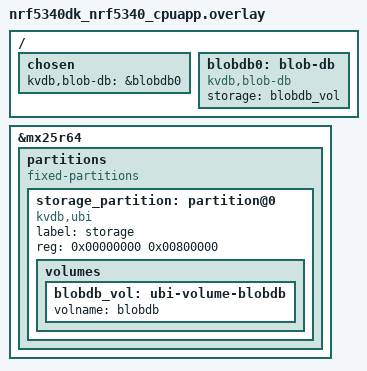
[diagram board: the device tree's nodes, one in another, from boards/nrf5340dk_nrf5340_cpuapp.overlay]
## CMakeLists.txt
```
#-------------------------------------------------------------------------------
# app_cbor_persondb — CBOR person/credential database over the L2 Map shape
#
# Copyright (c) 2026
# SPDX-License-Identifier: Apache-2.0

cmake_minimum_required(VERSION 3.13.1)
find_package(Zephyr REQUIRED HINTS $ENV{ZEPHYR_BASE})

project(app_cbor_persondb LANGUAGES C)

# One directory per layer, added bottom-up (DESIGN.md §7). Each subdirectory
# contributes its own sources and publishes its own header directory, so the
# build file has the same shape as the design — and a new dependency between
# layers is a visible edit here, not an #include someone slipped in.
#
#   ui/        frontends: parse and print only                    (F15)
#     |
#   scenario/  operations on a population: fill, verify, measure   (F14)
#     |   \_______________________
#     |                           |
#   persondb/                  dataset/
#     the person management       the synthetic population: a pure
#     API, and the only layer     function of an index. Uses persondb's
#     that touches storage        record type; touches no storage.
#     (F12, R-H)                                              (F6)
#     \__ person_cbor: the wire format, private to persondb
#
add_subdirectory(dataset)
add_subdirectory(persondb)
add_subdirectory(scenario)
add_subdirectory(ui)
```

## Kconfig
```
# app_cbor_persondb — Kconfig entry point.
#
# Copyright (c) 2026
# SPDX-License-Identifier: Apache-2.0

module = APP_CBOR_PERSONDB
module-str = APP_CBOR_PERSONDB
source "subsys/logging/Kconfig.template.log_config"

choice APP_CBOR_PERSONDB_FRONTEND
	prompt "Frontend"
	default APP_CBOR_PERSONDB_FRONTEND_BENCH
	help
	  Both frontends drive the same scenario layer (DESIGN.md §9); they
	  differ only in how the operations are invoked and rendered.

config APP_CBOR_PERSONDB_FRONTEND_BENCH
	bool "Automatic benchmark run"
	help
	  Unattended: open, prepare, fill (resuming in batches), verify,
	  mutate, re-verify, benchmark, report, exit. The source of RESULTS.md.

config APP_CBOR_PERSONDB_FRONTEND_SHELL
	bool "Interactive shell"
	select SHELL
	imply BLOB_DB_SHELL
	help
	  The same operations under "persondb <cmd>", for poking a live store
	  on the board — including power-cutting a fill and inspecting what
	  survived. The read-only "blob_db <cmd>" group (BLOB_DB_SHELL) comes
	  with it, to see how that data lies across the buckets.

endchoice

config APP_CBOR_PERSONDB_TUI
	bool "Full-screen browser under the shell (persondb tui)"
	default y
	depends on APP_CBOR_PERSONDB_FRONTEND_SHELL
	help
	  Adds "persondb tui": a VT100 full-screen view of every stored
	  person, with dialogs to add and delete persons, grant and revoke
	  permissions, add and remove cards, rename a person and set the
	  days their cards are valid. It draws over the shell's own terminal
	  and hands it back on 'q', Ctrl-C or Ctrl-D. Plain VT100 and DEC
	  line drawing, 80x24, so any serial terminal will do.

	  Costs ~3.4 KB of .bss (measured with nm): the page cache, the
	  selected person, a read buffer and 128 remembered page starts.
	  Nothing on the shell thread's stack beyond what the shell commands
	  already use.

# The shell frontend runs the scenario layer on the SHELL thread, not on main,
# and blob_db builds every slot in a CONFIG_BLOB_DB_MAX_PAYLOAD_LEN + 46 byte
# stack frame (FINDINGS.md B5, job 3). prj.conf sizes CONFIG_MAIN_STACK_SIZE for
# that chain — 19 870 B measured with -fstack-usage — but Zephyr's shell thread
# defaults to 2 048 B, so every persondb command overflowed it and halted the
# system on the first keystroke. Give the shell thread what main gets.
#
# Costs ~26 KB of RAM, and only when the shell frontend is selected.
config SHELL_STACK_SIZE
	default 28672 if APP_CBOR_PERSONDB_FRONTEND_SHELL

config APP_CBOR_PERSONDB_N_PERSONS
	int "Number of persons in the dataset"
	default 8000
	range 8 200000
	help
	  Dataset scale, and a FIXED CONSTANT OF THE BENCHMARK. Two runs are
	  only comparable if they used the same number, so treat changing it
	  as defining a new benchmark rather than tuning this one.

	  8 000 since DESIGN.md §6.5. It was 10 000, chosen once to put the
	  store at roughly half the nRF5340-DK's 8 MiB external flash. The
	  two-instance layout cannot reach that: the measured ceiling is
	  9 670 persons, because kvhash's bucket directory is a 16 384 B blob
	  that blob_db can no longer place once the store is about half full
	  (FINDINGS.md K13).

	  8 000 is the re-sized constant, not the ceiling. The gap is
	  deliberate: 9 670 is where a FRESH fill dies, and a benchmark that
	  sits at its own cliff fails later, on the DK, hours into a fill, for
	  reasons that look random. 17 % under it, the store holds at 41.3 %
	  live across repeated fill/mutate/bench rounds with no drift — that
	  was measured over three consecutive runs, not assumed.

	  The fill percentage remains an output, not a target (DESIGN.md
	  §6.3). If the stack gets more efficient and the same 8 000 persons
	  come to occupy 30 %, that is the improvement being measured — do
	  not raise this to compensate. Raising it to chase the ceiling is
	  how the number stops meaning anything.

	  Lower it for a quick run; the smoke scenario in sample.yaml uses 200.

config APP_CBOR_PERSONDB_FILL_BATCH
	int "Persons per resumable fill batch"
	default 256
	range 1 65536
	help
	  Progress is committed to the superblock after each batch, so an
	  interrupted fill resumes from the last committed count instead of
	  starting over. Replaying a partial batch rewrites identical values,
	  so replay is free.

config APP_CBOR_PERSONDB_VERIFY_SAMPLES
	int "Persons verified per run"
	default 256
	range 1 65536
	help
	  Verifying all 8 000 persons costs roughly 5 minutes per pass on the
	  DK, so a run checks a deterministic spread instead. Every sampled
	  person is compared field by field against the generator, and each of
	  its cards is resolved back through the credential index.

config APP_CBOR_PERSONDB_MUTATE_COUNT
	int "Persons touched per mutation round"
	default 64
	range 1 4096
	help
	  Each run revokes the previous revision's temporary cards and grants
	  the next revision's, exercising both fail-safe orderings
	  (DESIGN.md F5) and proving across a reboot that the previous run's
	  writes survived.

config APP_CBOR_PERSONDB_BENCH_SAMPLES
	int "Operations per benchmark phase"
	default 200
	range 1 65536

config APP_CBOR_PERSONDB_BENCH_DESTROY
	bool "End the benchmark run by destroying the store (destructive)"
	depends on !APP_CBOR_PERSONDB_FRESH_START
	help
	  After the report, run `persondb_destroy()` on the loaded store and
	  time it, then rebuild an empty store in its place and time that:
	  `scenario reset`, measured. Both print as bench lines with their
	  flash traffic split by class, like every other phase.

	  This is the scoped teardown, not a wipe. blob_db is shared, so the
	  store releases its own blobs one delete at a time and leaves
	  everything else alone (DESIGN.md §12.4); its cost follows what the
	  store holds, and the erases that its tombstones force are the part
	  that costs seconds on real flash.

	  Off by default because it throws away what the run built: the next
	  boot fills from empty again, so every run becomes a first run and
	  no run proves the previous one's writes survived. Excludes
	  FRESH_START, which would wipe the partition inside the timed
	  rebuild.

config APP_CBOR_PERSONDB_FRESH_START
	bool "Wipe the whole blob_db partition at boot (benchmarks)"
	help
	  Drop everything before opening, so this run behaves like the very
	  first one: the clean start a benchmark measures from. This is a
	  blob_db_erase_all() of the whole partition, so it also removes
	  anything else stored there, not only this store — `persondb reset`
	  is the scoped way to start over. On native_sim prefer the
	  --flash_erase command-line option.

# Sourced last on purpose. Kconfig resolves a symbol's `default` to the first
# one it parses, so any Zephyr default this app overrides — see
# CONFIG_SHELL_STACK_SIZE above — must be stated before this line, not after.
menu "Zephyr"
source "Kconfig.zephyr"
endmenu
```

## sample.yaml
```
sample:
  description: CBOR person/credential database over the L2 Map shape
  name: cbor-persondb
common:
  tags: [storage, cbor]
tests:
  # The headline configuration. Build only: a 10 000-person fill is roughly
  # 2.5 h on the DK's QSPI NOR (DESIGN.md §6.2).
  app.cbor_persondb.bench:
    build_only: true

  # Same app, interactive frontend.
  app.cbor_persondb.shell:
    build_only: true
    extra_configs:
      - CONFIG_APP_CBOR_PERSONDB_FRONTEND_SHELL=y

  # Small enough to actually run in CI, so fill -> verify -> mutate ->
  # re-verify stays regression-tested even though the headline config never
  # runs here.
  app.cbor_persondb.smoke:
    platform_allow: native_sim
    extra_configs:
      - CONFIG_APP_CBOR_PERSONDB_N_PERSONS=200
      # No map-count override: the app is two kvhash instances (DESIGN.md
      # §12.2) and the default is the shipped layout.
      - CONFIG_APP_CBOR_PERSONDB_VERIFY_SAMPLES=64
      - CONFIG_APP_CBOR_PERSONDB_BENCH_SAMPLES=20
    harness: console
    harness_config:
      type: multi_line
      ordered: true
      regex:
        - "VERIFY PASS"
        # A8: the sizing rule of DESIGN.md §6.1 holds for this configuration.
        # Without this line a fill that overflows a bucket still prints both
        # of the others, and CI calls it a pass.
        - "bucket overflows: 0"
        - "persondb: done"

  # The smoke run with kvhash spilling on: values over 64 B (every person
  # record, ~380 B) go to a blob of their own; credentials (23 B) stay
  # inline. Keeps the spill path regression-tested in a real application.
  app.cbor_persondb.smoke.spill64:
    platform_allow: native_sim
    extra_configs:
      - CONFIG_APP_CBOR_PERSONDB_N_PERSONS=200
      - CONFIG_APP_CBOR_PERSONDB_VERIFY_SAMPLES=64
      - CONFIG_APP_CBOR_PERSONDB_BENCH_SAMPLES=20
      - CONFIG_BLOB_CONTAINER_KVHASH_VAL_INLINE_MAX=64
    harness: console
    harness_config:
      type: multi_line
      ordered: true
      regex:
        - "VERIFY PASS"
        - "bucket overflows: 0"
        - "persondb: done"

  # The smoke run, ended by destroying the store and building an empty one
  # (RESULTS.md §11). Spilling is on so the destroy also has to release
  # every bucket's spilled blobs, which is the path that can leak.
  app.cbor_persondb.smoke.destroy:
    platform_allow: native_sim
    extra_configs:
      - CONFIG_APP_CBOR_PERSONDB_N_PERSONS=200
      - CONFIG_APP_CBOR_PERSONDB_VERIFY_SAMPLES=64
      - CONFIG_APP_CBOR_PERSONDB_BENCH_SAMPLES=20
      - CONFIG_BLOB_CONTAINER_KVHASH_VAL_INLINE_MAX=64
      - CONFIG_APP_CBOR_PERSONDB_BENCH_DESTROY=y
    harness: console
    harness_config:
      type: multi_line
      ordered: true
      regex:
        - "VERIFY PASS"
        - "bucket overflows: 0"
        - "bench destroy:\\s+1 ops"
        - "bench create:\\s+1 ops"
        - "persondb: done"
```

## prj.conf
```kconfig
CONFIG_LOG=y
CONFIG_APP_CBOR_PERSONDB_LOG_LEVEL_INF=y

# The storage slice this app uses: L1 + L1.5 + the L2 Map provider and the Set
# shape over it. kvdb (L3) is deliberately absent. The application is three L2
# containers -- one people map, one credential map, one set of right names --
# with every root in one app-owned superblock under a single rootreg key. L3 gives a database a name and a backend record; this
# app needs neither, and taking it would put a kvdb instance around each
# container and a registry entry behind each instance. See DESIGN.md §12.
CONFIG_BLOB_DB=y
CONFIG_BLOB_ROOTREG=y
CONFIG_BLOB_CONTAINER_KVHASH=y
CONFIG_BLOB_CONTAINER_SET_OVER_MAP=y

# CBOR — Zephyr's own codec. Canonical encoding keeps a record's bytes a pure
# function of its content, which is what lets verification compare encodings
# rather than decoded structs.
CONFIG_ZCBOR=y
CONFIG_ZCBOR_CANONICAL=y

# kvhash derives both its bucket size and its bucket count from this one
# symbol: a bucket may hold MAX_PAYLOAD bytes and a map (MAX_PAYLOAD-8)/8
# buckets, so map capacity is ~MAX_PAYLOAD^2/8. blob_db_mount() checks that the
# value is usable on the target geometry (FINDINGS.md B9/B10).
#
# It must be large enough that ONE people map holds the dataset, because the
# app is two containers and no longer shards (DESIGN.md §12.2). 16384 puts the
# fullest bucket at 30 % of the ceiling -- the same posture as the 66 % the
# sixteen-shard build kept, with the margin measured the same way
# (tools/sizing.py).
#
# It also caps the store at 9 670 persons, 49.9 % of the part. The directory is
# a 16 384 B blob and blob_db must place each rewritten copy in one erase block;
# past half-full it cannot, and a first insert into a fresh bucket fails while
# 1 KB blobs still fit. That is K13, and it is why the 10 000-person benchmark
# scale no longer fits. 8192 would hold 11 787 -- by running the fullest bucket
# at 99 % of a silent, unrecoverable cliff (K2). Capacity is not the only axis.
#
# It is NOT set to the 32 722 B the geometry sustains, and the reason is a
# finding rather than a preference. At 32 722 the map takes its maximum 4089
# buckets, so the bucket directory is a 32 720 B blob -- and two copies of it
# plus their slot headers are 65 484 B of a 65 488 B erase block. The directory
# then owns an entire block, blob_db compacts on every rewrite, and the fill
# dies at person 36 with -ENOSPC. See FINDINGS.md K12: the geometry's largest
# payload builds a map that cannot be written to.
#
# What 16384 still costs is left in plain sight: kvhash reads the WHOLE
# directory on every get, set and delete (K11), so 2047 buckets = 16 384 B read
# per operation, 3.8x the bytes the sixteen-shard build moved. That is the
# measurement (RESULTS.md), not a knob to tune back down.
CONFIG_BLOB_DB_MAX_PAYLOAD_LEN=16384

# Count flash operations and bytes at the storage seam. Without this the app
# can only *model* what it costs the flash — and the model that held before
# blob_db learned to walk buckets by slot header ("one whole sector per map
# operation") was wrong by 20x afterwards. Measure, do not model.
CONFIG_BLOB_DB_IOSTATS=y

# Keep the storage stack quiet so per-op logging does not perturb timings.
CONFIG_BLOB_DB_LOG_LEVEL_WRN=y
CONFIG_ROOTREG_LOG_LEVEL_WRN=y
CONFIG_BLOB_CONTAINER_KVHASH_LOG_LEVEL_WRN=y

# Sized from measured ARM frames (-fstack-usage), not guessed. The deepest
# chain is the write path:
#
#   scenario_bench 2464 + persondb_person_put 824 + kvhash_set 88
#                       + blob_db_update 64 + append_slot 16430  =  19 870 B
#
# append_slot alone is 83 % of that, because blob_db builds every slot in a
# CONFIG_BLOB_DB_MAX_PAYLOAD_LEN + 46 byte *stack* frame (FINDINGS.md B5,
# job 3). That frame used to be 4200 B and a 12 KB stack held it. Raising the
# payload so one map can hold the dataset multiplies it by four -- B5 job 3
# went from a remark to the dominant term in this application's RAM budget,
# which is the finding, not an argument for sharding again.
#
# Staging the slot in the existing .bss scratch -- Stage 1 of the large-payloads
# proposal -- would take this back to ~3.5 KB.
#
# 28 KB leaves ~1.4x margin over the measured worst case.
CONFIG_MAIN_STACK_SIZE=28672
```

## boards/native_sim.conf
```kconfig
# Match the DK: blob_db stages a whole 64 KB erase block in .bss.
CONFIG_BLOB_DB_SECTOR_BUF_SIZE=65536

# blob_db invalidates bucket headers by programming 0x00 over already-
# programmed magic bytes (1->0 only, legal on real NOR without an erase). The
# flash simulator rejects program-over-non-erased by default.
CONFIG_FLASH_SIMULATOR_DOUBLE_WRITES=y

# zephyr-ubi's heap, sized to the DK geometry the overlay mirrors: 8 B per
# erase block (128 of 64 KB, so 1 KB) plus a handle and scratch buffer at
# attach and a second pair during a format. Same value as the DK board file,
# so a native_sim run proves it is enough.
CONFIG_BLOB_DB_UBI_HEAP_SIZE=6144
```

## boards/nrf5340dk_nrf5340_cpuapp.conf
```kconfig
# blob_db stages a whole erase block in .bss; the MX25R6435F's is 64 KB.
CONFIG_BLOB_DB_SECTOR_BUF_SIZE=65536

# zephyr-ubi's heap: 8 B per erase block (128 of 64 KB here, so 1 KB) plus a
# handle and scratch buffer at attach and a second pair during a format. The
# default assumes 4 KB blocks and would reserve 20 KB.
CONFIG_BLOB_DB_UBI_HEAP_SIZE=6144
```

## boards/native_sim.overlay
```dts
/*
 * Model the DK's storage exactly: 8 MiB of partition in 64 KB sectors.
 *
 * The erase-block-size override is load-bearing, not cosmetic. blob_db can
 * only rebind a payload that fits *twice* between the bucket header and the
 * sector end, so on native_sim's default 4 KB sectors the sustainable payload
 * is 2026 B — below the 4096 this app configures, which would leave a full
 * kvhash bucket writable once and never updatable (FINDINGS.md B10).
 * blob_db_mount() checks the same inequality against the real geometry
 * (FINDINGS.md B9/B10 — findings this app raised).
 *
 * The write-block-size override is load-bearing too: it is part of the store
 * format. blob_db rounds every slot up to it and the scan recomputes the
 * stride from it, recorded nowhere on flash. The DK's nrf_qspi_nor reports 4;
 * at the simulator's default of 1 a board image reads as a near-empty store,
 * and the flash counters drift from the board's by up to ~2 %. At 4 they are
 * identical to the DK's, run for run (FINDINGS.md B13).
 */

&flashcontroller0 {
	reg = <0x00000000 DT_SIZE_M(16)>;
};

&flash0 {
	reg = <0x00000000 DT_SIZE_M(16)>;
	erase-block-size = <65536>;
	write-block-size = <4>;
};

&storage_partition {
	reg = <0x00800000 DT_SIZE_M(8)>;
};
```

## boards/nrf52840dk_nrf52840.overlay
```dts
/*
 * Same store as the nRF5340-DK: the nRF52840-DK carries the same MX25R6435F
 * (8 MiB, 64 KB sectors) on QSPI, so the store lives there and every geometry
 * in RESULTS.md applies unchanged.
 */

/delete-node/ &storage_partition;

&mx25r64 {
	partitions {
		compatible = "fixed-partitions";
		#address-cells = <1>;
		#size-cells = <1>;

		storage_partition: partition@0 {
			label = "storage";
			reg = <0x00000000 0x00800000>;
		};
	};
};
```

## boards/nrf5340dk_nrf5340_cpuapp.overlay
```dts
/*
 * Run against the on-board MX25R6435F QSPI NOR (8 MiB, 64 KB sectors) rather
 * than internal flash: R-E is stated in terms of the DK's *external* flash,
 * and 64 KB sectors are the geometry every number in RESULTS.md assumes.
 */

/delete-node/ &storage_partition;

&mx25r64 {
	partitions {
		compatible = "fixed-partitions";
		#address-cells = <1>;
		#size-cells = <1>;

		storage_partition: partition@0 {
			compatible = "kvdb,ubi";
			label = "storage";
			reg = <0x00000000 0x00800000>;

			volumes {
				blobdb_vol: ubi-volume-blobdb {
					volname = "blobdb";
				};
			};
		};
	};
};

/*
 * The blob_db store on the volume above. No "automount": this program mounts,
 * formats and unmounts the store itself, which keeps working exactly as
 * before (doc/proposals/2026-10-12-devicetree-configuration.md §3.5).
 */
/ {
	chosen {
		kvdb,blob-db = &blobdb0;
	};

	blobdb0: blob-db {
		compatible = "kvdb,blob-db";
		storage = <&blobdb_vol>;
	};
};
```

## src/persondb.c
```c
/*
 * Copyright (c) 2026
 * SPDX-License-Identifier: Apache-2.0
 *
 * persondb — the person management API, on L2 map_ops + rootreg + blob_db.
 *
 * Layout (DESIGN.md §12). One registry key, one app-owned superblock, N + 1
 * maps; everything is reachable from the integer 1 (P5), and boot costs two
 * sector reads rather than the eighteen an equivalent set of named kvdb
 * instances would:
 *
 *   rootreg[ ROOTREG_KEY('PADB', 1) ] -> superblock -> people_root[0..N-1]
 *                                                   -> cred_root
 *
 * This is the only file in the application that mentions a key, a shard, a
 * blob id or a map operation.
 */

#include <errno.h>
#include <stdio.h>
#include <string.h>

#include <zephyr/kernel.h>
#include <zephyr/logging/log.h>
#include <zephyr/storage/flash_map.h>

#include <app/lib/blob_db.h>
#include <app/lib/containers/kvhash.h>
#include <app/lib/rootreg.h>

#include "person_cbor.h"
#include "persondb.h"

LOG_MODULE_REGISTER(persondb, CONFIG_APP_CBOR_PERSONDB_LOG_LEVEL);

#define PADB_MAGIC        0x50414442u /* 'PADB' */
#define PADB_ROOTREG_KEY  ROOTREG_KEY(PADB_MAGIC, 1)
#define SUPERBLOCK_VERSION 1

#define N_PEOPLE_MAPS CONFIG_APP_CBOR_PERSONDB_PEOPLE_MAPS

/* Person keys are "pXXXXXXXX": fixed width, so every key is 9 bytes and the
 * entry-size arithmetic in DESIGN.md §6 has no variance from key length. */
#define PERSON_KEY_SZ 10

/*
 * kvhash's capacity formula is private to kvhash.c, so an application that
 * wants a full-size map has to restate it — FINDINGS.md K9(c). Worse, the
 * request is silently clamped: ask for more than this and `create` returns 0
 * having given you fewer buckets, with no way to read back what you got
 * (K9(b), K10). Restating it here at least makes the assumption checkable.
 */
#define KVHASH_DIR_HDR_LEN 8u
#define KVHASH_MAX_BUCKETS ((CONFIG_BLOB_DB_MAX_PAYLOAD_LEN - KVHASH_DIR_HDR_LEN) / 8u)

/*
 * A payload must fit twice between the bucket header and the sector end, or
 * it can be written once and never rewritten (FINDINGS.md B10). Nothing in
 * blob_db checks this (B9), so the app does — at build time against the
 * geometry it expects, and again at open() against the geometry it got.
 */
#define SLOT_OVERHEAD    14u
#define BUCKET_HDR_LEN   16u
#define MIN_SECTOR_FOR_PAYLOAD \
	(((CONFIG_BLOB_DB_MAX_PAYLOAD_LEN + SLOT_OVERHEAD) * 2u) + BUCKET_HDR_LEN)

BUILD_ASSERT(CONFIG_BLOB_DB_SECTOR_BUF_SIZE >= MIN_SECTOR_FOR_PAYLOAD,
	     "CONFIG_BLOB_DB_MAX_PAYLOAD_LEN cannot be rewritten in a sector "
	     "this size — see FINDINGS.md B10");
BUILD_ASSERT(KVHASH_MAX_BUCKETS >= 2, "payload too small for a bucket directory");

struct persondb {
	bool                  open;
	uint64_t              sb_id;
	struct superblock     sb;
	const struct map_ops *ops;
	struct persondb_stat  st;
};

/* One store per image: blob_db is a single global instance and the whole
 * stack is single-threaded (C7), so a second handle would be a lie. */
static struct persondb g_db;

/* -- plumbing ----------------------------------------------------------- */

static uint32_t fnv1a32(const void *data, size_t len)
{
	const uint8_t *p = data;
	uint32_t h = 0x811c9dc5u;

	for (size_t i = 0; i < len; i++) {
		h ^= p[i];
		h *= 0x01000193u;
	}
	return h;
}

/* Shard on a hash of the id rather than the id itself, so persondb stays
 * independent of how the caller numbers people — a caller allocating ids
 * sequentially and one allocating them sparsely get the same distribution,
 * which is what DESIGN.md §6.1's sizing assumes. */
static uint64_t people_root(struct persondb *db, uint32_t id)
{
	return db->sb.people_root[fnv1a32(&id, sizeof(id)) % db->sb.n_people_maps];
}

static void person_key(char *buf, uint32_t id)
{
	snprintf(buf, PERSON_KEY_SZ, "p%08X", (unsigned)id);
}

/* Every map operation is counted here because no layer below counts anything
 * (FINDINGS.md B3). A get is two blob_db operations — directory then bucket
 * (K11) — and a set or delete is three; each of those moves a whole sector
 * (B1). That is the entire basis of the amplification figures. */
static int map_get(struct persondb *db, uint64_t root, const char *key,
		   void *out, size_t out_sz, size_t *out_len)
{
	db->st.map_gets++;
	db->st.blob_ops += 2;
	return db->ops->get(root, key, strlen(key), out, out_sz, out_len);
}

static int map_set(struct persondb *db, uint64_t root, const char *key,
		   const void *val, size_t len)
{
	int rc;

	db->st.map_sets++;
	db->st.blob_ops += 3;
	rc = db->ops->set(root, key, strlen(key), val, len);
	if (rc == -ENOSPC) {
		/* A single bucket overflowed while the medium is nearly empty
		 * (K2). DESIGN.md §6.1 sizes this away; if it fires, that
		 * sizing rule was wrong (A8). */
		db->st.enospc_hits++;
		LOG_ERR("bucket overflow on key '%s' — see FINDINGS.md K2", key);
	}
	return rc;
}

static int map_del(struct persondb *db, uint64_t root, const char *key)
{
	db->st.map_dels++;
	db->st.blob_ops += 3;
	return db->ops->del(root, key, strlen(key));
}

static int cred_put(struct persondb *db, const char *card, uint32_t person_id)
{
	uint8_t buf[CRED_CBOR_MAX];
	size_t len;
	int rc = cred_cbor_encode(person_id, buf, sizeof(buf), &len);

	if (rc != 0) {
		return rc;
	}
	return map_set(db, db->sb.cred_root, card, buf, len);
}

static int sb_commit(struct persondb *db)
{
	uint8_t buf[SUPERBLOCK_CBOR_MAX];
	size_t len;
	int rc = superblock_cbor_encode(&db->sb, buf, sizeof(buf), &len);

	if (rc != 0) {
		return rc;
	}
	db->st.blob_ops++;
	return blob_db_update(db->sb_id, buf, len);
}

/* -- geometry ----------------------------------------------------------- */

/*
 * blob_db knows the partition size, the sector size and the bucket count, and
 * exposes none of them (FINDINGS.md B3). To answer "how full is the store, as
 * a fraction of the external flash" — which is the whole of R-E — the
 * application has to rediscover the geometry through the same flash_area API
 * the library used, behind its back.
 */
static int geometry(size_t *partition_bytes, size_t *sector_bytes)
{
	const struct flash_area *fa;
	struct flash_sector sector;
	uint32_t count = 1;
	int rc = flash_area_open(PARTITION_ID(storage_partition), &fa);

	if (rc < 0) {
		return rc;
	}

	*partition_bytes = fa->fa_size;
	rc = flash_area_sectors(fa, &count, &sector);
	if ((rc < 0 && rc != -ENOMEM) || count == 0) {
		flash_area_close(fa);
		return rc < 0 ? rc : -EIO;
	}
	*sector_bytes = sector.fs_size;

	flash_area_close(fa);
	return 0;
}

/* -- lifecycle ---------------------------------------------------------- */

/*
 * Build a virgin store: allocate the map roots, create each map, and bind the
 * superblock LAST. That single write publishes the whole structure atomically.
 *
 * A crash before it leaves the maps allocated and unreferenced, and blob_db
 * has no reachability GC — compaction reclaims tombstones and superseded
 * slots only — so those blobs are lost until a format (FINDINGS.md B8). It is
 * the same window kvdb has at kvdb.c:118, and the reason P7's "no permanent
 * leak" does not currently hold for any multi-blob structure.
 */
static int create_store(struct persondb *db, uint32_t n_persons)
{
	struct superblock *sb = &db->sb;

	memset(sb, 0, sizeof(*sb));
	sb->version = SUPERBLOCK_VERSION;
	sb->n_people_maps = N_PEOPLE_MAPS;
	sb->n_persons = n_persons;

	const struct map_config cfg = { .initial_capacity = KVHASH_MAX_BUCKETS };

	for (uint8_t i = 0; i < sb->n_people_maps; i++) {
		sb->people_root[i] = blob_db_alloc_id();
		if (sb->people_root[i] == 0) {
			return -EIO;
		}
		int rc = db->ops->create(sb->people_root[i], &cfg);

		if (rc != 0) {
			return rc;
		}
	}

	sb->cred_root = blob_db_alloc_id();
	if (sb->cred_root == 0) {
		return -EIO;
	}

	int rc = db->ops->create(sb->cred_root, &cfg);

	if (rc != 0) {
		return rc;
	}

	LOG_INF("created store: %u people maps + 1 credential map, "
		"%u buckets each, %u persons planned",
		sb->n_people_maps, (unsigned)KVHASH_MAX_BUCKETS, n_persons);

	return sb_commit(db);   /* the commit point */
}

int persondb_open(struct persondb **out, uint32_t n_persons)
{
	struct persondb *db = &g_db;
	size_t partition_bytes, sector_bytes;
	int rc;

	if (out == NULL) {
		return -EINVAL;
	}

	memset(&db->st, 0, sizeof(db->st));
	db->ops = &kvhash_map_ops;

	rc = geometry(&partition_bytes, &sector_bytes);
	if (rc != 0) {
		LOG_ERR("cannot read partition geometry: %d", rc);
		return rc;
	}

	/* The build-time assert used CONFIG_BLOB_DB_SECTOR_BUF_SIZE, which is
	 * only an upper bound. This is the real geometry. */
	if (MIN_SECTOR_FOR_PAYLOAD > sector_bytes) {
		LOG_ERR("payload %u needs a sector of at least %u B, this "
			"flash has %zu B — a full bucket could be written once "
			"and never rewritten (FINDINGS.md B10)",
			(unsigned)CONFIG_BLOB_DB_MAX_PAYLOAD_LEN,
			(unsigned)MIN_SECTOR_FOR_PAYLOAD, sector_bytes);
		return -ENOTSUP;
	}

	db->st.partition_bytes = partition_bytes;
	db->st.sector_bytes = sector_bytes;

	rc = rootreg_get_or_create(PADB_ROOTREG_KEY, &db->sb_id);
	if (rc != 0) {
		LOG_ERR("rootreg: %d", rc);
		return rc;
	}

	uint8_t buf[SUPERBLOCK_CBOR_MAX];
	size_t got = 0;

	db->st.blob_ops++;
	rc = blob_db_get(db->sb_id, buf, sizeof(buf), &got);
	if (rc == -ENOENT || (rc == 0 && got == 0)) {
		/* Virgin, or a crash before a previous create's commit. */
		rc = create_store(db, n_persons);
	} else if (rc == 0) {
		rc = superblock_cbor_decode(buf, got, &db->sb);
		if (rc == 0 && db->sb.version != SUPERBLOCK_VERSION) {
			LOG_ERR("superblock version %u, expected %u",
				db->sb.version, SUPERBLOCK_VERSION);
			rc = -EIO;
		}
		if (rc == 0 && db->sb.n_people_maps != N_PEOPLE_MAPS) {
			/* The shard count is baked into where every key lives,
			 * so a build that disagrees cannot read the store.
			 * kvhash cannot rehash (K3) and cannot be iterated
			 * (K6), so there is no migration path — say so plainly
			 * rather than returning wrong answers. */
			LOG_ERR("store has %u people maps, this build has %u — "
				"reformat required (FINDINGS.md K3/K6)",
				db->sb.n_people_maps, N_PEOPLE_MAPS);
			rc = -ENOTSUP;
		}
	}
	if (rc != 0) {
		return rc;
	}

	db->st.buckets_per_map = KVHASH_MAX_BUCKETS;
	db->open = true;
	*out = db;
	return 0;
}

int persondb_close(struct persondb *db)
{
	if (db) {
		db->open = false;
	}
	return 0;
}

/* -- enrollment --------------------------------------------------------- */

int persondb_person_put(struct persondb *db, const struct persondb_person *p)
{
	uint8_t buf[PERSON_CBOR_MAX];
	char key[PERSON_KEY_SZ];
	size_t len;
	int rc = person_cbor_encode(p, buf, sizeof(buf), &len);

	if (rc != 0) {
		return rc;
	}

	person_key(key, p->id);
	rc = map_set(db, people_root(db, p->id), key, buf, len);
	if (rc != 0) {
		return rc;
	}

	/* Record first, index second (F5): a crash here leaves a card the
	 * person lists but that resolves to nothing, which denies. */
	for (uint8_t i = 0; i < p->n_cards; i++) {
		rc = cred_put(db, p->card[i], p->id);
		if (rc != 0) {
			return rc;
		}
	}
	return 0;
}

int persondb_person_get(struct persondb *db, uint32_t id,
			struct persondb_person *out)
{
	uint8_t buf[PERSON_CBOR_MAX];
	char key[PERSON_KEY_SZ];
	size_t len = 0;

	person_key(key, id);

	int rc = map_get(db, people_root(db, id), key, buf, sizeof(buf), &len);

	if (rc != 0) {
		return rc;
	}
	return person_cbor_decode(buf, len, out);
}

int persondb_person_delete(struct persondb *db, uint32_t id)
{
	struct persondb_person p;
	int rc = persondb_person_get(db, id, &p);

	if (rc != 0) {
		return rc;
	}

	/* Credentials first (F5): after each delete the card already resolves
	 * to nothing, so every crash point in this loop denies. */
	for (uint8_t i = 0; i < p.n_cards; i++) {
		rc = map_del(db, db->sb.cred_root, p.card[i]);
		if (rc != 0 && rc != -ENOENT) {
			return rc;
		}
	}

	char key[PERSON_KEY_SZ];

	person_key(key, id);
	return map_del(db, people_root(db, id), key);
}

/* -- credentials -------------------------------------------------------- */

int persondb_card_assign(struct persondb *db, uint32_t person_id,
			 const char *card)
{
	struct persondb_person p;
	int rc = persondb_person_get(db, person_id, &p);

	if (rc != 0) {
		return rc;
	}

	for (uint8_t i = 0; i < p.n_cards; i++) {
		if (strcmp(p.card[i], card) == 0) {
			return 0;   /* idempotent: replay of a batch is free */
		}
	}
	if (p.n_cards >= PERSONDB_CARDS_MAX) {
		return -ENOSPC;
	}

	snprintf(p.card[p.n_cards], sizeof(p.card[0]), "%s", card);
	p.n_cards++;

	/* Person first, index second — see F5. The reverse order would leave a
	 * credential that grants access on behalf of a person who does not
	 * list it: a crash that fails *open*. */
	uint8_t buf[PERSON_CBOR_MAX];
	size_t len;
	char key[PERSON_KEY_SZ];

	rc = person_cbor_encode(&p, buf, sizeof(buf), &len);
	if (rc != 0) {
		return rc;
	}
	person_key(key, person_id);
	rc = map_set(db, people_root(db, person_id), key, buf, len);
	if (rc != 0) {
		return rc;
	}

	return cred_put(db, card, person_id);
}

int persondb_card_revoke(struct persondb *db, const char *card)
{
	uint32_t person_id;
	int rc = persondb_card_owner(db, card, &person_id);

	if (rc != 0) {
		return rc;
	}

	/* Index first, person second — the mirror of assignment, fail-safe for
	 * the same reason: after this write the card resolves to nothing. */
	rc = map_del(db, db->sb.cred_root, card);
	if (rc != 0 && rc != -ENOENT) {
		return rc;
	}

	struct persondb_person p;

	rc = persondb_person_get(db, person_id, &p);
	if (rc != 0) {
		return rc;
	}

	uint8_t n = 0;

	for (uint8_t i = 0; i < p.n_cards; i++) {
		if (strcmp(p.card[i], card) != 0) {
			if (n != i) {
				memcpy(p.card[n], p.card[i], sizeof(p.card[0]));
			}
			n++;
		}
	}
	if (n == p.n_cards) {
		return 0;   /* already absent from the record */
	}
	p.n_cards = n;

	uint8_t buf[PERSON_CBOR_MAX];
	size_t len;
	char key[PERSON_KEY_SZ];

	rc = person_cbor_encode(&p, buf, sizeof(buf), &len);
	if (rc != 0) {
		return rc;
	}
	person_key(key, person_id);
	return map_set(db, people_root(db, person_id), key, buf, len);
}

int persondb_card_owner(struct persondb *db, const char *card,
			uint32_t *person_id)
{
	uint8_t buf[CRED_CBOR_MAX];
	size_t len = 0;
	int rc = map_get(db, db->sb.cred_root, card, buf, sizeof(buf), &len);

	if (rc != 0) {
		return rc;
	}
	return cred_cbor_decode(buf, len, person_id);
}

/* -- permissions -------------------------------------------------------- */

static int person_store(struct persondb *db, const struct persondb_person *p)
{
	uint8_t buf[PERSON_CBOR_MAX];
	char key[PERSON_KEY_SZ];
	size_t len;
	int rc = person_cbor_encode(p, buf, sizeof(buf), &len);

	if (rc != 0) {
		return rc;
	}
	person_key(key, p->id);
	return map_set(db, people_root(db, p->id), key, buf, len);
}

int persondb_permission_grant(struct persondb *db, uint32_t person_id,
			      const char *perm)
{
	struct persondb_person p;
	int rc = persondb_person_get(db, person_id, &p);

	if (rc != 0) {
		return rc;
	}
	for (uint8_t i = 0; i < p.n_perms; i++) {
		if (strcmp(p.perm[i], perm) == 0) {
			return 0;
		}
	}
	if (p.n_perms >= PERSONDB_PERMS_MAX) {
		return -ENOSPC;
	}
	snprintf(p.perm[p.n_perms], sizeof(p.perm[0]), "%s", perm);
	p.n_perms++;

	/* One record, one atomic map set. Permissions live only in the person
	 * record, so — unlike credentials — there is no second structure to
	 * keep in step and no ordering to get right. That is a consequence of
	 * refusing to denormalize (D2), not an accident. */
	return person_store(db, &p);
}

int persondb_permission_revoke(struct persondb *db, uint32_t person_id,
			       const char *perm)
{
	struct persondb_person p;
	int rc = persondb_person_get(db, person_id, &p);

	if (rc != 0) {
		return rc;
	}

	uint8_t n = 0;

	for (uint8_t i = 0; i < p.n_perms; i++) {
		if (strcmp(p.perm[i], perm) != 0) {
			if (n != i) {
				memcpy(p.perm[n], p.perm[i], sizeof(p.perm[0]));
			}
			n++;
		}
	}
	if (n == p.n_perms) {
		return -ENOENT;
	}
	p.n_perms = n;
	return person_store(db, &p);
}

/* -- the decision ------------------------------------------------------- */

int persondb_check(struct persondb *db, const char *card, const char *perm,
		   uint32_t now, enum persondb_decision *out,
		   struct persondb_person *who)
{
	struct persondb_person local;
	struct persondb_person *p = who ? who : &local;
	uint32_t person_id;

	int rc = persondb_card_owner(db, card, &person_id);

	if (rc == -ENOENT) {
		*out = PERSONDB_UNKNOWN_CARD;
		return 0;
	}
	if (rc != 0) {
		return rc;   /* never a grant */
	}

	rc = persondb_person_get(db, person_id, p);
	if (rc == -ENOENT) {
		/* The index resolved to a person that is not there. Neither
		 * write ordering in this file can produce that (F5), so it is
		 * real damage — deny, and say so. */
		LOG_ERR("credential %s resolves to absent person %u", card,
			person_id);
		*out = PERSONDB_UNKNOWN_CARD;
		return 0;
	}
	if (rc != 0) {
		return rc;
	}

	if (now < p->valid_from || now >= p->valid_until) {
		*out = PERSONDB_EXPIRED;
		return 0;
	}

	for (uint8_t i = 0; i < p->n_perms; i++) {
		if (strcmp(p->perm[i], perm) == 0) {
			*out = PERSONDB_GRANTED;
			return 0;
		}
	}
	*out = PERSONDB_DENIED;
	return 0;
}

const char *persondb_decision_str(enum persondb_decision d)
{
	switch (d) {
	case PERSONDB_GRANTED:      return "GRANTED";
	case PERSONDB_DENIED:       return "DENIED";
	case PERSONDB_UNKNOWN_CARD: return "UNKNOWN_CARD";
	case PERSONDB_EXPIRED:      return "EXPIRED";
	default:                    return "?";
	}
}

/* -- app-owned persistent state ----------------------------------------- */

int persondb_progress_get(struct persondb *db, uint32_t *populated,
			  uint32_t *rev)
{
	if (populated) {
		*populated = db->sb.populated;
	}
	if (rev) {
		*rev = db->sb.rev;
	}
	return 0;
}

int persondb_progress_set(struct persondb *db, uint32_t populated, uint32_t rev)
{
	db->sb.populated = populated;
	db->sb.rev = rev;
	return sb_commit(db);
}

/* -- introspection ------------------------------------------------------ */

int persondb_stat(struct persondb *db, struct persondb_stat *out)
{
	*out = db->st;
	out->n_persons = db->sb.n_persons;
	out->populated = db->sb.populated;
	out->rev = db->sb.rev;
	out->n_people_maps = db->sb.n_people_maps;
	return 0;
}

void persondb_counters_reset(struct persondb *db)
{
	db->st.map_gets = 0;
	db->st.map_sets = 0;
	db->st.map_dels = 0;
	db->st.blob_ops = 0;
}
```

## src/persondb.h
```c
/*
 * Copyright (c) 2026
 * SPDX-License-Identifier: Apache-2.0
 *
 * persondb — the person management API, internal to this application.
 *
 * Domain vocabulary only: persons, credentials, permissions, decisions. No
 * keys, no shards, no blob ids, no CBOR. Everything above this header is
 * written against these operations, which is what lets the storage layout in
 * persondb.c be replaced without touching the scenario layer or either
 * frontend (DESIGN.md F12; checked as acceptance criterion A7).
 *
 * Concurrency: single-threaded, inherited from blob_db's v1 contract. The
 * caller serializes every call — including across different structures, since
 * kvhash's scratch buffers are shared by every map in the image
 * (FINDINGS.md K7).
 */

#ifndef APP_CBOR_PERSONDB_PERSONDB_H_
#define APP_CBOR_PERSONDB_PERSONDB_H_

#include <stdbool.h>
#include <stddef.h>
#include <stdint.h>

#ifdef __cplusplus
extern "C" {
#endif

/* Field capacities. Fixed, so a person is a plain value type that lives on
 * the stack — no heap anywhere in this application (P2/P3). */
#define PERSONDB_NAME_MAX   31
#define PERSONDB_DEPT_MAX   23
#define PERSONDB_TITLE_MAX  23
#define PERSONDB_PERM_MAX   23
#define PERSONDB_PERMS_MAX  22
#define PERSONDB_CARD_LEN   14   /* 7-byte UID as hex, like a real NFC card */
#define PERSONDB_CARDS_MAX   5   /* 4 permanent + 1 temporary (mutation round) */
#define PERSONDB_PIN_LEN    16

/** A person. Permissions and cards are text, per R-C2 / R-C3. */
struct persondb_person {
	uint32_t id;
	char     name [PERSONDB_NAME_MAX  + 1];
	char     dept [PERSONDB_DEPT_MAX  + 1];
	char     title[PERSONDB_TITLE_MAX + 1];
	uint32_t valid_from;                    /* epoch seconds, inclusive */
	uint32_t valid_until;                   /* epoch seconds, exclusive */
	uint8_t  pin_hash[PERSONDB_PIN_LEN];
	uint8_t  n_perms;
	char     perm[PERSONDB_PERMS_MAX][PERSONDB_PERM_MAX + 1];
	uint8_t  n_cards;
	char     card[PERSONDB_CARDS_MAX][PERSONDB_CARD_LEN + 1];
};

/** The outcome of an access request. */
enum persondb_decision {
	PERSONDB_GRANTED = 0,
	PERSONDB_DENIED,        /* card known, permission not held */
	PERSONDB_UNKNOWN_CARD,  /* no such credential */
	PERSONDB_EXPIRED,       /* card known, outside the validity window */
};

/**
 * @brief What the store looks like from outside.
 *
 * Most of this exists because no layer below reports it (FINDINGS.md B3, K10):
 * the partition size is read from devicetree, and the op counters are kept by
 * this module so amplification can be computed at all.
 */
struct persondb_stat {
	uint32_t n_persons;          /* dataset size recorded at create time */
	uint32_t populated;          /* persons written so far */
	uint32_t rev;                /* mutation revision */
	uint8_t  n_people_maps;
	uint16_t buckets_per_map;    /* what kvhash actually gave us (K9) */

	size_t   partition_bytes;    /* from devicetree — see B3 */
	size_t   sector_bytes;       /* erase-block size, ditto */

	uint32_t enospc_hits;        /* F11: bucket overflows, never expected */

	/* Flash traffic, counted here because nothing else counts it. Every
	 * map operation is at least two blob_db operations (K11), and every
	 * blob_db operation moves a whole sector (B1). */
	uint64_t map_gets;
	uint64_t map_sets;
	uint64_t map_dels;
	uint64_t blob_ops;
};

/** Opaque handle; the instance is owned by persondb.c (one store per image). */
struct persondb;

/* -- lifecycle ---------------------------------------------------------- */

/**
 * @brief Attach to the store, building it if this is a virgin device.
 *
 * Requires blob_db_mount() and rootreg_init() to have run. Verifies that the
 * configured payload size is actually usable on this flash geometry before
 * touching anything (FINDINGS.md B9/B10).
 *
 * @param db          (out) handle
 * @param n_persons   dataset size to record when creating; ignored when
 *                    attaching to a store that already exists
 *
 * @retval 0        ready
 * @retval -ENOTSUP the configured payload does not fit this geometry
 * @retval -EIO     flash error or a corrupt superblock
 */
int persondb_open(struct persondb **db, uint32_t n_persons);

/** Detach. The store is untouched. */
int persondb_close(struct persondb *db);

/* -- enrollment --------------------------------------------------------- */

/**
 * @brief Insert or replace a person record, and index every card it lists.
 *
 * @retval 0       stored
 * @retval -ENOSPC a kvhash bucket overflowed (K2) — counted in the stat block
 */
int persondb_person_put(struct persondb *db, const struct persondb_person *p);

/**
 * @retval 0       found
 * @retval -ENOENT no such person
 */
int persondb_person_get(struct persondb *db, uint32_t id,
			struct persondb_person *out);

/** Remove a person and every credential pointing at it. */
int persondb_person_delete(struct persondb *db, uint32_t id);

/* -- credentials -------------------------------------------------------- */

/**
 * @brief Assign a card to a person.
 *
 * Writes the person record first and the index second. There is no multi-key
 * transaction (C8), so a crash between the two must be survivable in one
 * direction only: this order leaves a card the person lists but that resolves
 * to nothing, which *denies*. The reverse order would leave a credential
 * granting access on behalf of a person who does not list it.
 */
int persondb_card_assign(struct persondb *db, uint32_t person_id,
			 const char *card);

/**
 * @brief Revoke a card.
 *
 * Deletes the index entry first and rewrites the person second — the mirror
 * of assignment, and fail-safe for the same reason: after the first write the
 * card already resolves to nothing.
 */
int persondb_card_revoke(struct persondb *db, const char *card);

/**
 * @retval 0       resolved; *person_id set
 * @retval -ENOENT unknown credential
 */
int persondb_card_owner(struct persondb *db, const char *card,
			uint32_t *person_id);

/* -- permissions -------------------------------------------------------- */

/** Add @p perm to a person, if not already held. */
int persondb_permission_grant(struct persondb *db, uint32_t person_id,
			      const char *perm);

/** Remove @p perm from a person. */
int persondb_permission_revoke(struct persondb *db, uint32_t person_id,
			       const char *perm);

/* -- the decision (R-D) ------------------------------------------------- */

/**
 * @brief Resolve a credential and decide whether it grants @p perm at @p now.
 *
 * Implemented the obvious way: resolve the card to a person id, load the
 * person, check the validity window, compare permission strings. It does not
 * shortcut the decode, and the credential index holds nothing but a person id
 * — no cached permission bitmask (DESIGN.md D2). The cost of that honesty is
 * measured rather than avoided: two map gets, which by B1/K11 is four
 * whole-sector reads.
 *
 * @param who (optional) receives the person on any decision but UNKNOWN_CARD
 *
 * @retval 0     a decision was reached; *out holds it
 * @retval -EIO  the store could not be read — never treated as a grant
 */
int persondb_check(struct persondb *db, const char *card, const char *perm,
		   uint32_t now, enum persondb_decision *out,
		   struct persondb_person *who);

/** Human-readable form of a decision, for logs and the shell. */
const char *persondb_decision_str(enum persondb_decision d);

/* -- app-owned persistent state ----------------------------------------- */

/**
 * @brief Read the fill progress and mutation revision.
 *
 * Kept in the app's own superblock rather than a separate store, so
 * committing progress is one atomic blob_db_update (DESIGN.md §12).
 */
int persondb_progress_get(struct persondb *db, uint32_t *populated,
			  uint32_t *rev);

/** Commit fill progress and revision. Atomic. */
int persondb_progress_set(struct persondb *db, uint32_t populated,
			  uint32_t rev);

/* -- introspection ------------------------------------------------------ */

int persondb_stat(struct persondb *db, struct persondb_stat *out);

/** Zero the traffic counters, so a phase can be measured in isolation. */
void persondb_counters_reset(struct persondb *db);

#ifdef __cplusplus
}
#endif

#endif /* APP_CBOR_PERSONDB_PERSONDB_H_ */
```
